# STM32H745BGT6@M4 register map
File version: 1.0
STM32H745BGT6@M4,STM32H745BGT6@M7,STM32H745BIT3@M4,STM32H745BIT3@M7,STM32H745BIT6@M4,STM32H745BIT6@M7,STM32H745BIT7@M4,STM32H745BIT7@M7,STM32H745IGK6@M4,STM32H745IGK6@M7,STM32H745IGT6@M4,STM32H745IGT6@M7,STM32H745IIK3@M4,STM32H745IIK3@M7,STM32H745IIK6@M4,STM32H745IIK6@M7,STM32H745IIK7@M4,STM32H745IIK7@M7,STM32H745IIT3@M4,STM32H745IIT3@M7,STM32H745IIT6@M4,STM32H745IIT6@M7,STM32H745IIT7@M4,STM32H745IIT7@M7,STM32H745XGH6@M4,STM32H745XGH6@M7,STM32H745XIH3@M4,STM32H745XIH3@M7,STM32H745XIH6@M4,STM32H745XIH6@M7,STM32H745XIH7@M4,STM32H745XIH7@M7,STM32H745ZGT6@M4,STM32H745ZGT6@M7,STM32H745ZIT3@M4,STM32H745ZIT3@M7,STM32H745ZIT6@M4,STM32H745ZIT6@M7,STM32H745ZIT7@M4,STM32H745ZIT7@M7,STM32H747AGI6@M4,STM32H747AGI6@M7,STM32H747AII6@M4,STM32H747AII6@M7,STM32H747BGT6@M4,STM32H747BGT6@M7,STM32H747BIT6@M4,STM32H747BIT6@M7,STM32H747IGT6@M4,STM32H747IGT6@M7,STM32H747IIT6@M4,STM32H747IIT6@M7,STM32H747XGH6@M4,STM32H747XGH6@M7,STM32H747XIH6@M4,STM32H747XIH6@M7,STM32H747ZIY6@M4,STM32H747ZIY6@M7,STM32H755BIT3@M4,STM32H755BIT3@M7,STM32H755BIT6@M4,STM32H755BIT6@M7,STM32H755BIT7@M4,STM32H755BIT7@M7,STM32H755IIK3@M4,STM32H755IIK3@M7,STM32H755IIK6@M4,STM32H755IIK6@M7,STM32H755IIK7@M4,STM32H755IIK7@M7,STM32H755IIT3@M4,STM32H755IIT3@M7,STM32H755IIT6@M4,STM32H755IIT6@M7,STM32H755IIT7@M4,STM32H755IIT7@M7,STM32H755XIH3@M4,STM32H755XIH3@M7,STM32H755XIH6@M4,STM32H755XIH6@M7,STM32H755XIH7@M4,STM32H755XIH7@M7,STM32H755ZIT3@M4,STM32H755ZIT3@M7,STM32H755ZIT6@M4,STM32H755ZIT6@M7,STM32H755ZIT7@M4,STM32H755ZIT7@M7,STM3
Registers are 32-bit, access not given, reset 0x0 unless marked. A register's access mark holds for its fields unless they carry their own. Offsets are from the block's base; lines under a group give offsets from that group; [hi:lo] are bit positions; {n}, {i} and the like mark numbered series; 'fields as' and 'values as' point back to an identical list; <NAME> marks a mode.

## Memory map
0x40000000 TIM2
0x40000400 TIM3
0x40000800 TIM4
0x40000C00 TIM5
0x40001000 TIM6
0x40001400 TIM7
0x40001800 TIM12
0x40001C00 TIM13
0x40002000 TIM14
0x40002400 LPTIM1
0x40002C00 WWDG2
0x40003800 SPI2
0x40003C00 SPI3
0x40004000 SPDIFRX
0x40004400 USART2
0x40004800 USART3
0x40004C00 UART4
0x40005000 UART5
0x40005400 I2C1
0x40005800 I2C2
0x40005C00 I2C3
0x40006C00 CEC
0x40007400 DAC1
0x40007800 UART7
0x40007C00 UART8
0x40008400 CRS
0x40008800 SWPMI
0x40009000 OPAMP
0x40009400 MDIOS
0x4000A000 FDCAN1
0x4000A400 FDCAN2
0x4000A800 CANCCU
0x40010000 TIM1
0x40010400 TIM8
0x40011000 USART1
0x40011400 USART6
0x40013000 SPI1
0x40013400 SPI4
0x40014000 TIM15
0x40014400 TIM16
0x40014800 TIM17
0x40015000 SPI5
0x40015800 SAI1
0x40015C00 SAI2
0x40016000 SAI3
0x40017000 DFSDM1
0x40017400 HRTIM
0x40020000 DMA1
0x40020400 DMA2
0x40020800 DMAMUX1
0x40022300 ADC1
0x40022400 ADC2
0x40028000 ETH
0x40040000 USB1OTG_HS
0x40080000 USB2OTG_FS
0x48020000 DCMI
0x48021000 CRYPTO
0x48021400 HASH
0x48021800 RNG
0x48022400 SDMMC2
0x48022800 DLYBSDMMC2
0x48023000 RAMECC2
0x50000000 DSI
0x50001000 LTDC
0x50003000 WWDG1
0x52000000 MDMA
0x52001000 DMA2D
0x52002000 FLASH
0x52003000 JPEG
0x52004000 FMC
0x52005000 QUADSPI
0x52006000 DLYBQUADSPI
0x52007000 SDMMC1
0x52008000 DLYBSDMMC1
0x52009000 RAMECC1
0x58000000 EXTI
0x58000400 SYSCFG
0x58000C00 LPUART1
0x58001400 SPI6
0x58001C00 I2C4
0x58002400 LPTIM2
0x58002800 LPTIM3
0x58002C00 LPTIM4
0x58003000 LPTIM5
0x58003800 COMP2
0x58003800 COMP1
0x58003C00 VREFBUF
0x58004000 BKP
0x58004000 RTC
0x58004800 IWDG1
0x58004C00 IWDG2
0x58005400 SAI4
0x58020000 GPIOA
0x58020400 GPIOB
0x58020800 GPIOC
0x58020C00 GPIOD
0x58021000 GPIOE
0x58021400 GPIOF
0x58021800 GPIOG
0x58021C00 GPIOH
0x58022000 GPIOI
0x58022400 GPIOJ
0x58022800 GPIOK
0x58024400 RCC
0x58024800 PWR
0x58024C00 CRC
0x58025400 BDMA
0x58025800 DMAMUX2
0x58026300 ADC3
0x58026400 HSEM
0x58027000 RAMECC3

## TIM2
Base 0x40000000
Same registers: TIM3 0x40000400, TIM4 0x40000800, TIM5 0x40000C00
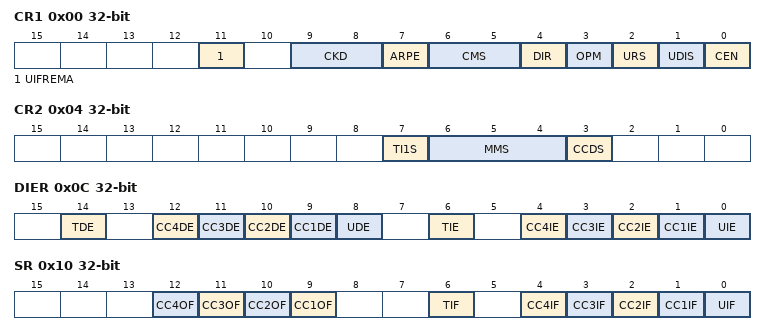
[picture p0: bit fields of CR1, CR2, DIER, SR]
0x00 CR1
  [11] UIFREMA, [9:8] CKD, [7] ARPE, [6:5] CMS, [4] DIR, [3] OPM, [2] URS, [1] UDIS, [0] CEN
0x04 CR2
  [7] TI1S, [6:4] MMS, [3] CCDS
0x08 SMCR
  [15] ETP, [14] ECE, [13:12] ETPS, [11:8] ETF, [7] MSM, [21:4] TS, [16:0] SMS
0x0C DIER
  [14] TDE, [n+8] CC{n}DE (n=1..4), [8] UDE, [6] TIE, [n] CC{n}IE (n=1..4), [0] UIE
0x10 SR
  [n+8] CC{n}OF (n=1..4), [6] TIF, [n] CC{n}IF (n=1..4), [0] UIF
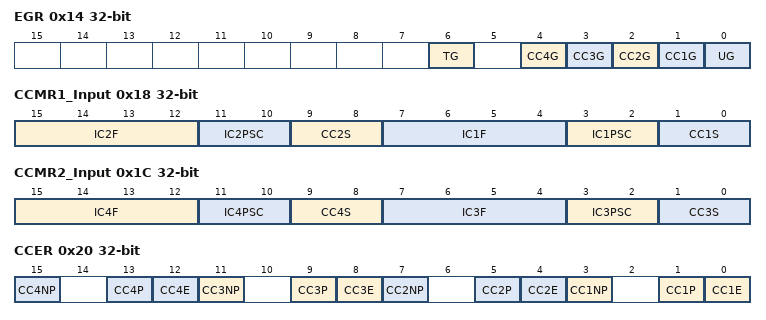
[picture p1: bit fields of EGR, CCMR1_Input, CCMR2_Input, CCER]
0x14 EGR
  [6] TG, [n] CC{n}G (n=1..4), [0] UG
0x18 CCMR1_Output
  [15] OC2CE, [24:12] OC2M, [11] OC2PE, [10] OC2FE, [9:8] CC2S, [7] OC1CE, [16:4] OC1M, [3] OC1PE, [2] OC1FE, [1:0] CC1S
0x18 CCMR1_Input
  [15:12] IC2F, [11:10] IC2PSC, [9:8] CC2S, [7:4] IC1F, [3:2] IC1PSC, [1:0] CC1S
0x1C CCMR2_Output
  [15] O24CE, [24:12] OC4M, [11] OC4PE, [10] OC4FE, [9:8] CC4S, [7] OC3CE, [16:4] OC3M, [3] OC3PE, [2] OC3FE, [1:0] CC3S
0x1C CCMR2_Input
  [15:12] IC4F, [11:10] IC4PSC, [9:8] CC4S, [7:4] IC3F, [3:2] IC3PSC, [1:0] CC3S
0x20 CCER
  [4n-1] CC{n}NP (n=1..4), [4n-3] CC{n}P (n=1..4), [4n-4] CC{n}E (n=1..4)
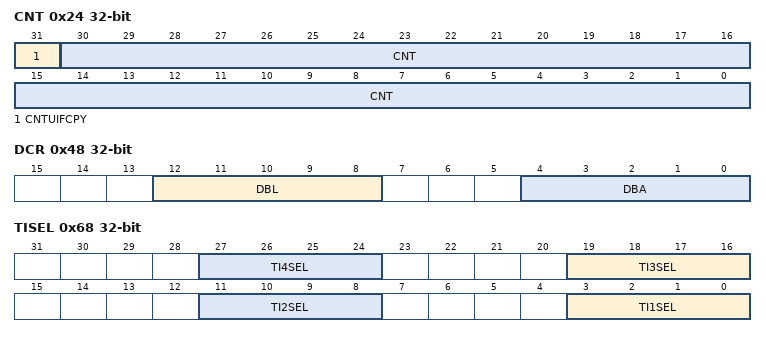
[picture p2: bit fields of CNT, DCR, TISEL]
0x24 CNT
  [31] CNTUIFCPY, [30:0] CNT
0x28 PSC
  [15:0] PSC
0x2C ARR
{0x30+4i} CCR{i} (i=1..4)
0x48 DCR
  [12:8] DBL, [4:0] DBA
0x4C DMAR
  [15:0] DMAB
0x60 AF1
  [17:14] ETRSEL
0x68 TISEL
  [8n-5:8n-8] TI{n}SEL (n=1..4)
